# N32MC47x_DP47x register map
Vendor: Nsingtech Ltd.; File version: 1.0
Registers are 32-bit, read-write, reset 0x0 unless marked. A register's access mark holds for its fields unless they carry their own. Offsets are from the block's base; [hi:lo] are bit positions.

## GPIOH — General purpose I/O
Base 0x4002DC00
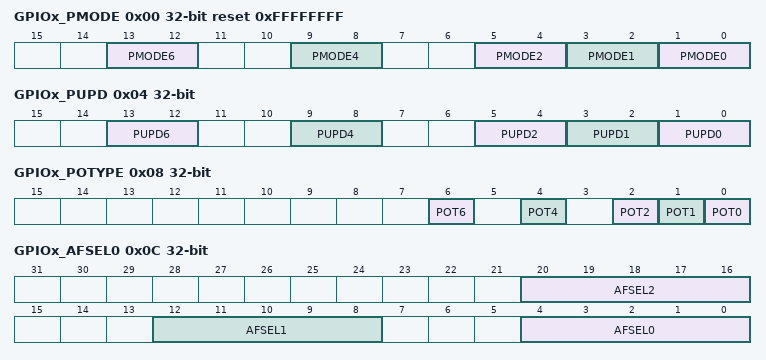
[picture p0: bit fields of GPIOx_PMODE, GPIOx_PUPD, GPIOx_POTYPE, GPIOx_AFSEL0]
0x00 GPIOx_PMODE reset 0xFFFFFFFF — GPIO mode description register
  [13:12] PMODE6, [9:8] PMODE4, [5:4] PMODE2, [3:2] PMODE1, [1:0] PMODE0
0x04 GPIOx_PUPD — GPIO pull-up/pull-down description register
  [13:12] PUPD6, [9:8] PUPD4, [5:4] PUPD2, [3:2] PUPD1, [1:0] PUPD0
0x08 GPIOx_POTYPE — GPIO output type definition
  [6] POT6, [4] POT4, [2] POT2, [1] POT1, [0] POT0
0x0C GPIOx_AFSEL0 — GPIO alternate function select register 0
  [20:16] AFSEL2, [12:8] AFSEL1, [4:0] AFSEL0
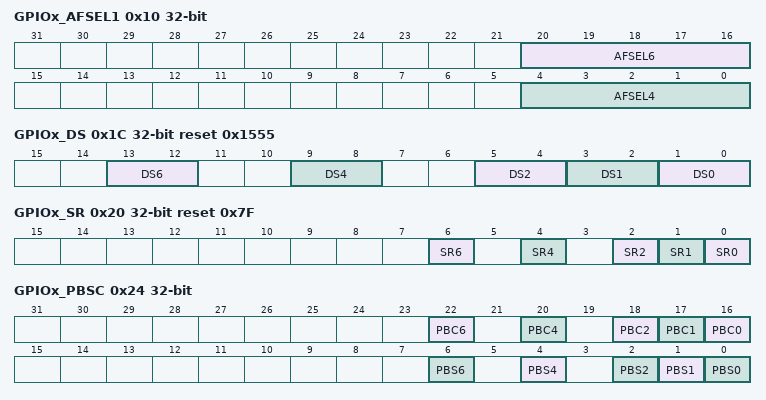
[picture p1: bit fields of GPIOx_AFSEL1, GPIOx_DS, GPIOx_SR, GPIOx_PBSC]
0x10 GPIOx_AFSEL1 — GPIO alternate function select register 1
  [20:16] AFSEL6, [4:0] AFSEL4
0x1C GPIOx_DS reset 0x1555 — GPIO driver strength configuration register
  [13:12] DS6, [9:8] DS4, [5:4] DS2, [3:2] DS1, [1:0] DS0
0x20 GPIOx_SR reset 0x7F — GPIO slew rate configuration register
  [6] SR6, [4] SR4, [2] SR2, [1] SR1, [0] SR0
0x24 GPIOx_PBSC wo — GPIO bit set/clear register
  [22] PBC6, [20] PBC4, [18] PBC2, [17] PBC1, [16] PBC0, [6] PBS6, [4] PBS4, [2] PBS2, [1] PBS1, [0] PBS0
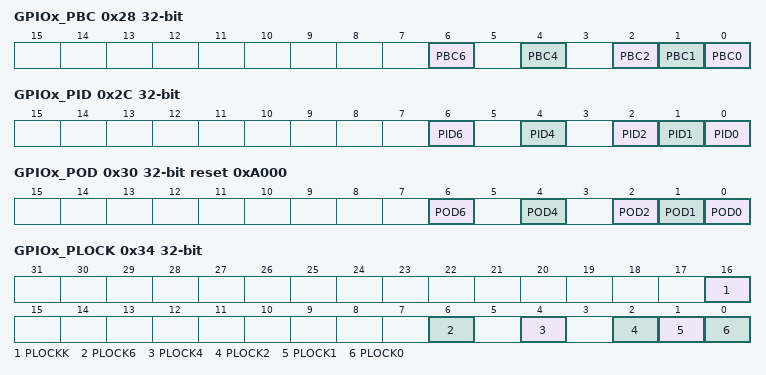
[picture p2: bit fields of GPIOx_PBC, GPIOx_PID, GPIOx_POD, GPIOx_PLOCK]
0x28 GPIOx_PBC wo — GPIO bit clear register
  [6] PBC6, [4] PBC4, [2] PBC2, [1] PBC1, [0] PBC0
0x2C GPIOx_PID ro — GPIO input data register
  [6] PID6, [4] PID4, [2] PID2, [1] PID1, [0] PID0
0x30 GPIOx_POD reset 0xA000 — GPIO output data register
  [6] POD6, [4] POD4, [2] POD2, [1] POD1, [0] POD0
0x34 GPIOx_PLOCK — GPIO configuration lock register
  [16] PLOCKK, [6] PLOCK6, [4] PLOCK4, [2] PLOCK2, [1] PLOCK1, [0] PLOCK0

## FLASH
Base 0x40022000
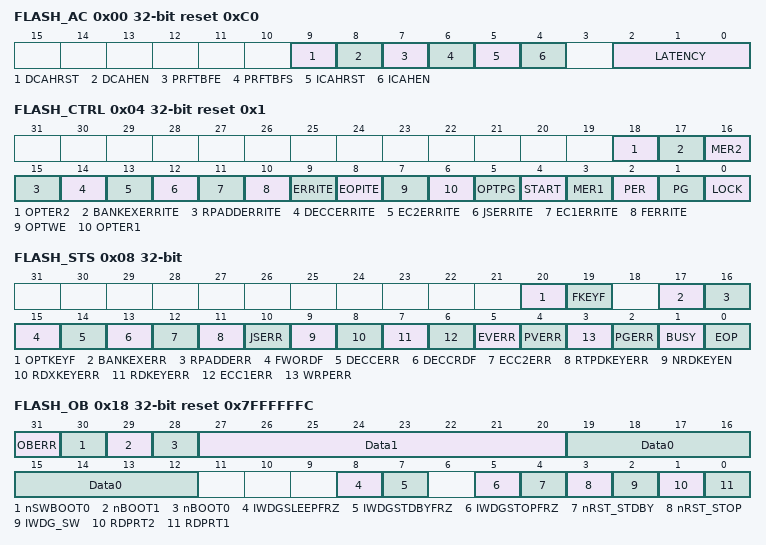
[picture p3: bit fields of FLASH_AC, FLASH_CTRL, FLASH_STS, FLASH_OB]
0x00 FLASH_AC reset 0xC0
  [9] DCAHRST — DCache reset
  [8] DCAHEN — DCache enable
  [7] PRFTBFE
  [6] PRFTBFS
  [5] ICAHRST
  [4] ICAHEN
  [2:0] LATENCY
0x04 FLASH_CTRL reset 0x1
  [18] OPTER2 — Erase option byte 0x1FFFA000 area
  [17] BANKEXERRITE — BANK swap error interrupt enable
  [16] MER2 — BANK2 mass erase
  [15] RPADDERRITE
  [14] DECCERRITE
  [13] EC2ERRITE
  [12] JSERRITE
  [11] EC1ERRITE
  [10] FERRITE
  [9] ERRITE
  [8] EOPITE
  [7] OPTWE
  [6] OPTER1 — Erase option byte 0x1FFFE000 area
  [5] OPTPG
  [4] START
  [3] MER1 — BANK1 mass erase
  [2] PER
  [1] PG
  [0] LOCK
0x08 FLASH_STS
  [20] OPTKEYF — Option byte unlock KEY1 flag
  [19] FKEYF — FLASH unlock KEY1 flag
  [17] BANKEXERR — BANK swap error
  [16] RPADDERR
  [15] FWORDF
  [14] DECCERR
  [13] DECCRDF
  [12] ECC2ERR
  [11] RTPDKEYERR
  [10] JSERR
  [9] NRDKEYEN
  [8] RDXKEYERR
  [7] RDKEYERR
  [6] ECC1ERR
  [5] EVERR
  [4] PVERR
  [3] WRPERR
  [2] PGERR
  [1] BUSY
  [0] EOP
0x0C FLASH_ADD
  [31:0] FADD
0x10 FLASH_KEY
  [31:0] FKEY
0x14 FLASH_OPTKEY
0x18 FLASH_OB reset 0x7FFFFFFC
  [31] OBERR, [30] nSWBOOT0, [29] nBOOT1, [28] nBOOT0, [27:20] Data1, [19:12] Data0, [8] IWDGSLEEPFRZ, [7] IWDGSTDBYFRZ, [5] IWDGSTOPFRZ, [4] nRST_STDBY, [3] nRST_STOP, [2] IWDG_SW, [1] RDPRT2, [0] RDPRT1
0x1C FLASH_WRP reset 0xFFFFFFFF
  [31:0] WRPT
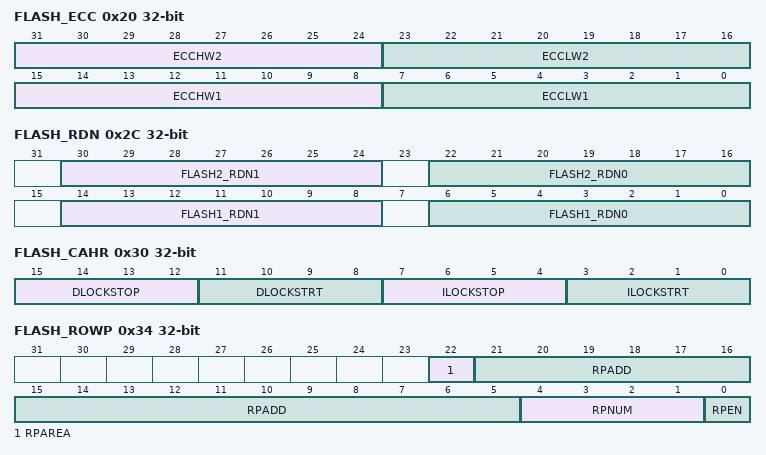
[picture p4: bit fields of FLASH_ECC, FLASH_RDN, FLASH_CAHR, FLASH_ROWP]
0x20 FLASH_ECC
  [31:24] ECCHW2 — BANK2 high 64-bit ECC value
  [23:16] ECCLW2 — BANK2 low 64-bit ECC value
  [15:8] ECCHW1 — BANK1 high 64-bit ECC value
  [7:0] ECCLW1 — BANK1 low 64-bit ECC value
0x2C FLASH_RDN
  [30:24] FLASH2_RDN1 — BANK2 Flash redundancy block page 1 address
  [22:16] FLASH2_RDN0 — BANK2 Flash redundancy block page 0 address
  [14:8] FLASH1_RDN1 — BANK1 Flash redundancy block page 1 address
  [6:0] FLASH1_RDN0 — BANK1 Flash redundancy block page 0 address
0x30 FLASH_CAHR
  [15:12] DLOCKSTOP — DCache lock stop
  [11:8] DLOCKSTRT — DCache lock start
  [7:4] ILOCKSTOP — iCache lock stop
  [3:0] ILOCKSTRT — iCache lock start
0x34 FLASH_ROWP
  [22] RPAREA, [21:5] RPADD, [4:1] RPNUM, [0] RPEN
0x38 CCM_WRP1
  [31:0] WRPTx
0x3C CCM_KEY
  [7:0] KEY
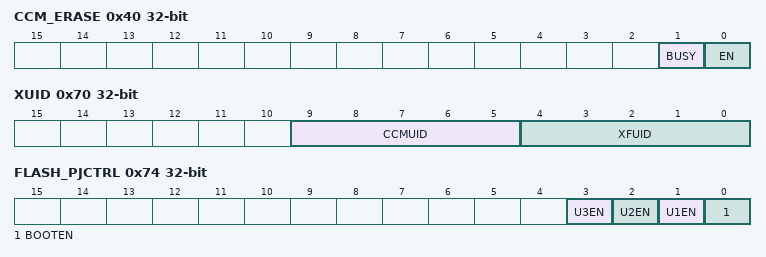
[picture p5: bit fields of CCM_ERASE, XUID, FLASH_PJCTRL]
0x40 CCM_ERASE
  [1] BUSY, [0] EN
0x48 CCM_MODE
  [0] EN
0x4C XSPI_DSTRADD
  [31:0] ADD
0x50 XSPI_DENDADD
  [31:0] ADD
0x54 FEMC_DSTRADD
  [31:0] ADD
0x58 FEMC_DENDADD
  [31:0] ADD
0x5C RTPD_KEY
0x60 JTAG_SEAL
  [7:0] DATA
0x64 RTPD_KEY_WCNT
  [2:0] CNT
0x6C XSPI_FEMC_DEN
  [0] EN
0x70 XUID
  [9:5] CCMUID, [4:0] XFUID
0x74 FLASH_PJCTRL — FLASH partition jump control register
  [3] U3EN — USER3 area jump control enable
  [2] U2EN — USER2 area jump control enable
  [1] U1EN — USER1 area jump control enable
  [0] BOOTEN — BOOT area jump control enable
